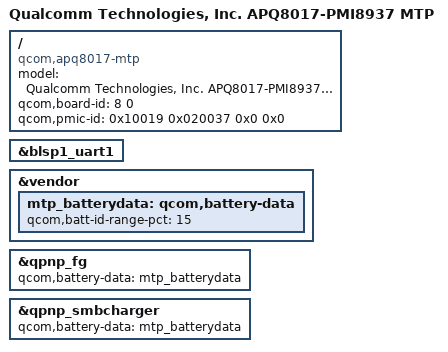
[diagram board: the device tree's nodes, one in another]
/*
 * Copyright (c) 2015-2018, The Linux Foundation. All rights reserved.
 *
 * This program is free software; you can redistribute it and/or modify
 * it under the terms of the GNU General Public License version 2 and
 * only version 2 as published by the Free Software Foundation.
 *
 * This program is distributed in the hope that it will be useful,
 * but WITHOUT ANY WARRANTY; without even the implied warranty of
 * MERCHANTABILITY or FITNESS FOR A PARTICULAR PURPOSE.  See the
 * GNU General Public License for more details.
 */

/dts-v1/;

#include "apq8017.dtsi"
#include "msm8917-mtp.dtsi"
#include "msm8917-pmi8937.dtsi"

/ {
	model = "Qualcomm Technologies, Inc. APQ8017-PMI8937 MTP";
	compatible = "qcom,apq8017-mtp", "qcom,apq8017", "qcom,mtp";
	qcom,board-id= <8 0>;
	qcom,pmic-id = <0x10019 0x020037 0x0 0x0>;
};

&blsp1_uart1 {
	status = "ok";
};

&vendor {
	mtp_batterydata: qcom,battery-data {
		qcom,batt-id-range-pct = <15>;
		#include "batterydata-itech-3000mah.dtsi"
		#include "batterydata-ascent-3450mAh.dtsi"
	};
};

&qpnp_fg {
	qcom,battery-data = <&mtp_batterydata>;
};

&qpnp_smbcharger {
	qcom,battery-data = <&mtp_batterydata>;
};
